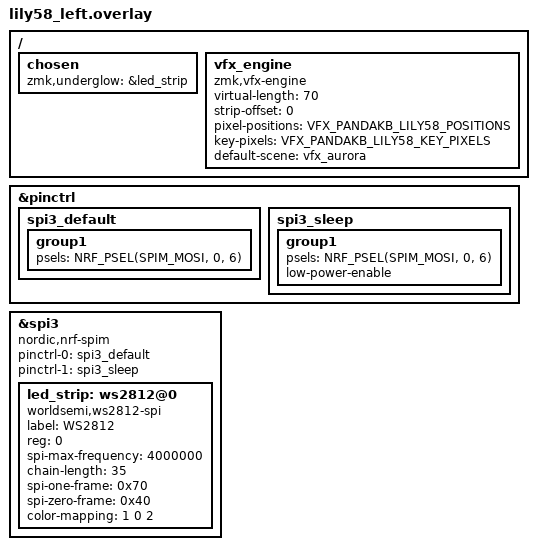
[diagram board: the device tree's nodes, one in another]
#include <dt-bindings/zmk/vfx.h>
#include <vfx/pandakb-lily58.dtsi>
#include <vfx/presets.dtsi>

/*
 * PandaKB Lily58 MX RGB underglow on nice_nano, left half.
 *
 * Filename matters: ZMK looks for <shield>_<board>.overlay or
 * <shield>.overlay, so this has to be lily58_left.overlay to be applied at
 * all. The right half is the same but for strip-offset.
 */

&pinctrl {
    spi3_default: spi3_default {
        group1 {
            psels = <NRF_PSEL(SPIM_MOSI, 0, 6)>;
        };
    };

    spi3_sleep: spi3_sleep {
        group1 {
            psels = <NRF_PSEL(SPIM_MOSI, 0, 6)>;
            low-power-enable;
        };
    };
};

&spi3 {
    compatible = "nordic,nrf-spim";
    status = "okay";

    pinctrl-0 = <&spi3_default>;
    pinctrl-1 = <&spi3_sleep>;
    pinctrl-names = "default", "sleep";

    led_strip: ws2812@0 {
        compatible = "worldsemi,ws2812-spi";
        label = "WS2812";

        /* SPI */
        reg = <0>; /* required for SPI bindings */
        spi-max-frequency = <4000000>;

        /* WS2812 */
        chain-length = <35>;
        spi-one-frame = <0x70>;
        spi-zero-frame = <0x40>;
        color-mapping = <1 0 2>;
    };
};

/ {
    chosen {
        zmk,underglow = &led_strip;
    };

    /* Effects are positioned across the whole keyboard, so each half renders
     * its own slice of a 70 pixel space and gradients carry across the seam.
     * The left half starts at 0; the right half starts at 35.
     */
    vfx_engine: vfx_engine {
        compatible = "zmk,vfx-engine";
        status = "okay";

        virtual-length = <70>;
        strip-offset = <0>;

        /* This board chains 6 downward-facing underglow LEDs before its 29
         * per-key ones, so neither the positions nor the key map follow the
         * plain 6x6 grid the generic Lily58 list assumes.
         */
        pixel-positions = <VFX_PANDAKB_LILY58_POSITIONS>;

        /* Without this a ripple starts at whatever pixel shares a number with
         * the key position, which is why pressing N lit the LED under 9.
         */
        key-pixels = <VFX_PANDAKB_LILY58_KEY_PIXELS>;

        default-scene = <&vfx_aurora>;
    };
};
